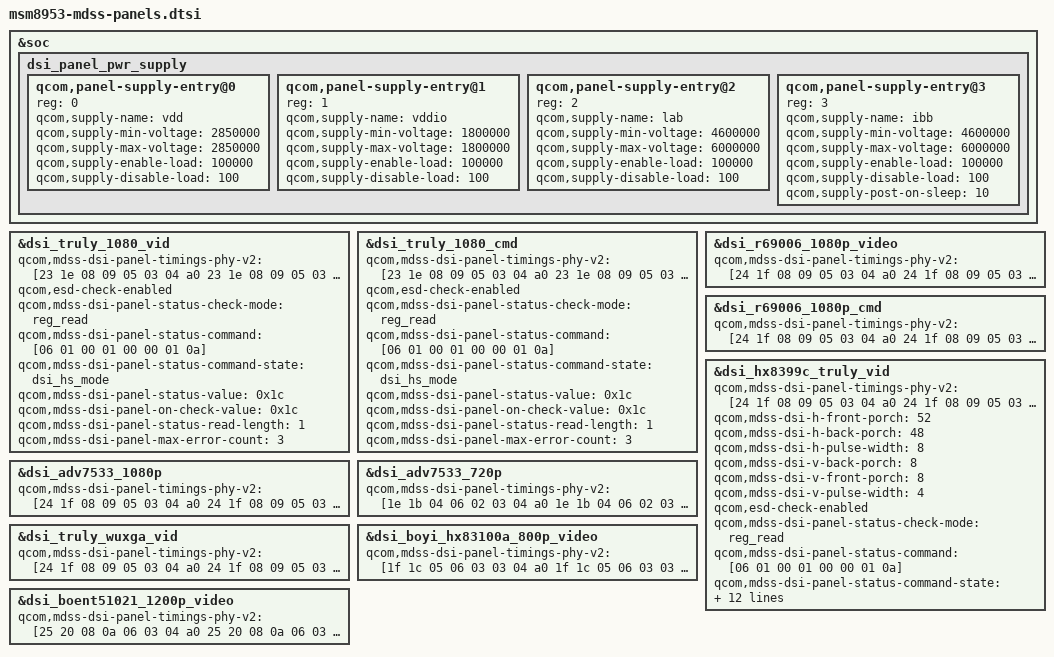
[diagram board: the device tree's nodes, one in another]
/* Copyright (c) 2015-2018, The Linux Foundation. All rights reserved.
 *
 * This program is free software; you can redistribute it and/or modify
 * it under the terms of the GNU General Public License version 2 and
 * only version 2 as published by the Free Software Foundation.
 *
 * This program is distributed in the hope that it will be useful,
 * but WITHOUT ANY WARRANTY; without even the implied warranty of
 * MERCHANTABILITY or FITNESS FOR A PARTICULAR PURPOSE.  See the
 * GNU General Public License for more details.
 */

#include "dsi-panel-sim-video.dtsi"
#include "dsi-panel-sim-dualmipi-video.dtsi"
#include "dsi-panel-sim-cmd.dtsi"
#include "dsi-panel-sim-dualmipi-cmd.dtsi"
#include "dsi-panel-truly-1080p-video.dtsi"
#include "dsi-panel-truly-1080p-cmd.dtsi"
#include "dsi-adv7533-1080p.dtsi"
#include "dsi-adv7533-720p.dtsi"
#include "dsi-panel-r69006-1080p-video.dtsi"
#include "dsi-panel-r69006-1080p-cmd.dtsi"
#include "dsi-panel-truly-wuxga-video.dtsi"
#include "dsi-panel-lt8912-480p-video.dtsi"
#include "dsi-panel-lt8912-1080p-video.dtsi"
#include "dsi-panel-hx8399c-fhd-plus-video.dtsi"
#include "dsi-panel-hx83100a-800p-video.dtsi"
#include "dsi-panel-boent51021-1200p-video.dtsi"

&soc {
	dsi_panel_pwr_supply: dsi_panel_pwr_supply {
		#address-cells = <1>;
		#size-cells = <0>;

		qcom,panel-supply-entry@0 {
			reg = <0>;
			qcom,supply-name = "vdd";
			qcom,supply-min-voltage = <2850000>;
			qcom,supply-max-voltage = <2850000>;
			qcom,supply-enable-load = <100000>;
			qcom,supply-disable-load = <100>;
		};

		qcom,panel-supply-entry@1 {
			reg = <1>;
			qcom,supply-name = "vddio";
			qcom,supply-min-voltage = <1800000>;
			qcom,supply-max-voltage = <1800000>;
			qcom,supply-enable-load = <100000>;
			qcom,supply-disable-load = <100>;
		};
		qcom,panel-supply-entry@2 {
			reg = <2>;
			qcom,supply-name = "lab";
			qcom,supply-min-voltage = <4600000>;
			qcom,supply-max-voltage = <6000000>;
			qcom,supply-enable-load = <100000>;
			qcom,supply-disable-load = <100>;
		};
		qcom,panel-supply-entry@3 {
			reg = <3>;
			qcom,supply-name = "ibb";
			qcom,supply-min-voltage = <4600000>;
			qcom,supply-max-voltage = <6000000>;
			qcom,supply-enable-load = <100000>;
			qcom,supply-disable-load = <100>;
			qcom,supply-post-on-sleep = <10>;
		};
	};
};

&dsi_truly_1080_vid {
	qcom,mdss-dsi-panel-timings-phy-v2 = [23 1e 08 09 05 03 04 a0
		23 1e 08 09 05 03 04 a0
		23 1e 08 09 05 03 04 a0
		23 1e 08 09 05 03 04 a0
		23 1a 08 09 05 03 04 a0];
	qcom,esd-check-enabled;
	qcom,mdss-dsi-panel-status-check-mode = "reg_read";
	qcom,mdss-dsi-panel-status-command = [06 01 00 01 00 00 01 0a];
	qcom,mdss-dsi-panel-status-command-state = "dsi_hs_mode";
	qcom,mdss-dsi-panel-status-value = <0x1c>;
	qcom,mdss-dsi-panel-on-check-value = <0x1c>;
	qcom,mdss-dsi-panel-status-read-length = <1>;
	qcom,mdss-dsi-panel-max-error-count = <3>;

};

&dsi_truly_1080_cmd {
	qcom,mdss-dsi-panel-timings-phy-v2 = [23 1e 08 09 05 03 04 a0
		23 1e 08 09 05 03 04 a0
		23 1e 08 09 05 03 04 a0
		23 1e 08 09 05 03 04 a0
		23 1a 08 09 05 03 04 a0];
	qcom,esd-check-enabled;
	qcom,mdss-dsi-panel-status-check-mode = "reg_read";
	qcom,mdss-dsi-panel-status-command = [06 01 00 01 00 00 01 0a];
	qcom,mdss-dsi-panel-status-command-state = "dsi_hs_mode";
	qcom,mdss-dsi-panel-status-value = <0x1c>;
	qcom,mdss-dsi-panel-on-check-value = <0x1c>;
	qcom,mdss-dsi-panel-status-read-length = <1>;
	qcom,mdss-dsi-panel-max-error-count = <3>;
};

&dsi_r69006_1080p_video {
	qcom,mdss-dsi-panel-timings-phy-v2 = [24 1f 08 09 05 03 04 a0
		24 1f 08 09 05 03 04 a0
		24 1f 08 09 05 03 04 a0
		24 1f 08 09 05 03 04 a0
		24 1b 08 09 05 03 04 a0];
};

&dsi_r69006_1080p_cmd{
	qcom,mdss-dsi-panel-timings-phy-v2 = [24 1f 08 09 05 03 04 a0
		24 1f 08 09 05 03 04 a0
		24 1f 08 09 05 03 04 a0
		24 1f 08 09 05 03 04 a0
		24 1b 08 09 05 03 04 a0];
};

&dsi_hx8399c_truly_vid {
	qcom,mdss-dsi-panel-timings-phy-v2 = [24 1f 08 09 05 03 04 a0
		24 1f 08 09 05 03 04 a0
		24 1f 08 09 05 03 04 a0
		24 1f 08 09 05 03 04 a0
		24 1c 08 09 05 03 04 a0];
	qcom,mdss-dsi-h-front-porch = <52>;
	qcom,mdss-dsi-h-back-porch = <48>;
	qcom,mdss-dsi-h-pulse-width = <8>;
	qcom,mdss-dsi-v-back-porch = <8>;
	qcom,mdss-dsi-v-front-porch = <8>;
	qcom,mdss-dsi-v-pulse-width = <4>;
	qcom,esd-check-enabled;
	qcom,mdss-dsi-panel-status-check-mode = "reg_read";
	qcom,mdss-dsi-panel-status-command = [06 01 00 01 00 00 01 0a];
	qcom,mdss-dsi-panel-status-command-state = "dsi_lp_mode";
	qcom,mdss-dsi-panel-status-value = <0x9d 0x9d 0x9d 0x9d>;
	qcom,mdss-dsi-panel-on-check-value = <0x9d 0x9d 0x9d 0x9d>;
	qcom,mdss-dsi-panel-status-read-length = <4>;
	qcom,mdss-dsi-panel-max-error-count = <3>;
	qcom,mdss-dsi-min-refresh-rate = <48>;
	qcom,mdss-dsi-max-refresh-rate = <60>;
	qcom,mdss-dsi-pan-enable-dynamic-fps;
	qcom,mdss-dsi-pan-fps-update =
		"dfps_immediate_porch_mode_vfp";
};

&dsi_adv7533_1080p {
	qcom,mdss-dsi-panel-timings-phy-v2 = [24 1f 08 09 05 03 04 a0
		24 1f 08 09 05 03 04 a0
		24 1f 08 09 05 03 04 a0
		24 1f 08 09 05 03 04 a0
		24 1b 08 09 05 03 04 a0];
};

&dsi_adv7533_720p {
	qcom,mdss-dsi-panel-timings-phy-v2 = [1e 1b 04 06 02 03 04 a0
		1e 1b 04 06 02 03 04 a0
		1e 1b 04 06 02 03 04 a0
		1e 1b 04 06 02 03 04 a0
		1e 0e 04 05 02 03 04 a0];
};

&dsi_truly_wuxga_vid {
	qcom,mdss-dsi-panel-timings-phy-v2 = [24 1f 08 09 05 03 04 a0
		24 1f 08 09 05 03 04 a0
		24 1f 08 09 05 03 04 a0
		24 1f 08 09 05 03 04 a0
		24 1c 08 09 05 03 04 a0];
};

&dsi_boyi_hx83100a_800p_video {
	qcom,mdss-dsi-panel-timings-phy-v2 = [1f 1c 05 06 03 03 04 a0
		1f 1c 05 06 03 03 04 a0
		1f 1c 05 06 03 03 04 a0
		1f 1c 05 06 03 03 04 a0
		1f 10 05 06 03 03 04 a0];
};

&dsi_boent51021_1200p_video {
	qcom,mdss-dsi-panel-timings-phy-v2 = [25 20 08 0a 06 03 04 a0
		25 20 08 0a 06 03 04 a0
		25 20 08 0a 06 03 04 a0
		25 20 08 0a 06 03 04 a0
		25 1d 08 0a 06 03 04 a0];
};
